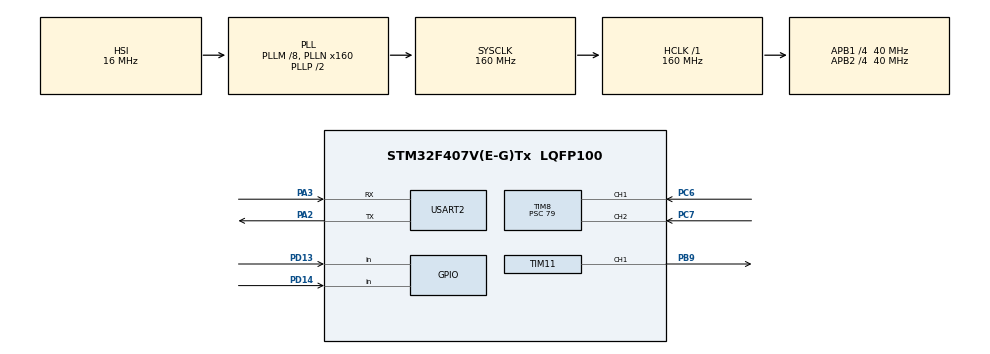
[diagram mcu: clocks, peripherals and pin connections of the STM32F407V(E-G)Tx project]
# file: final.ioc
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Mcu.Family=STM32F4
Mcu.Name=STM32F407V(E-G)Tx
Mcu.Package=LQFP100
NVIC.PriorityGroup=NVIC_PRIORITYGROUP_0
PA2.Mode=Asynchronous
PA2.Signal=USART2_TX
PA3.Mode=Asynchronous
PA3.Signal=USART2_RX
PB9.Signal=S_TIM11_CH1
PC6.Signal=S_TIM8_CH1
PC7.Signal=S_TIM8_CH2
PD13.Signal=GPIO_Input
PD14.Signal=GPIO_Input
ProjectManager.HeapSize=0x200
ProjectManager.StackSize=0x400
ProjectManager.TargetToolchain=STM32CubeIDE
RCC.48MHZClocksFreq_Value=45714285.71428572
RCC.AHBFreq_Value=160000000
RCC.APB1CLKDivider=RCC_HCLK_DIV4
RCC.APB1Freq_Value=40000000
RCC.APB1TimFreq_Value=80000000
RCC.APB2CLKDivider=RCC_HCLK_DIV4
RCC.APB2Freq_Value=40000000
RCC.APB2TimFreq_Value=80000000
RCC.CortexFreq_Value=160000000
RCC.HCLKFreq_Value=160000000
RCC.HSE_VALUE=8000000
RCC.HSI_VALUE=16000000
RCC.PLLM=8
RCC.PLLN=160
RCC.PLLQ=7
RCC.SYSCLKFreq_VALUE=160000000
RCC.SYSCLKSource=RCC_SYSCLKSOURCE_PLLCLK
RCC.VCOOutputFreq_Value=320000000
SH.S_TIM11_CH1.0=TIM11_CH1,PWM Generation1 CH1
SH.S_TIM8_CH1.0=TIM8_CH1,Input_Capture1_from_TI1
SH.S_TIM8_CH2.0=TIM8_CH2,TriggerSource_TI2FP2
SH.S_TIM8_CH2.1=TIM8_CH2,Input_Capture2_from_TI2
TIM11.Channel=TIM_CHANNEL_1
TIM11.Period=39999
TIM11.Prescaler=199
TIM8.Channel-Input_Capture1_from_TI1=TIM_CHANNEL_1
TIM8.Channel-Input_Capture2_from_TI2=TIM_CHANNEL_2
TIM8.ICPolarity_CH1=TIM_INPUTCHANNELPOLARITY_BOTHEDGE
TIM8.ICPolarity_CH2=TIM_INPUTCHANNELPOLARITY_BOTHEDGE
TIM8.Prescaler=79
USART2.VirtualMode=VM_ASYNC
VP_TIM11_VS_ClockSourceINT.Mode=Enable_Timer
VP_TIM8_VS_ControllerModeReset.Mode=Reset Mode
board=STM32F407G-DISC1

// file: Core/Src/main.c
/* USER CODE BEGIN Header */
/**
  ******************************************************************************
  * @file           : main.c
  * @brief          : Main program body
  ******************************************************************************
  * @attention
  *
  * Copyright (c) 2022 STMicroelectronics.
  * All rights reserved.
  *
  * This software is licensed under terms that can be found in the LICENSE file
  * in the root directory of this software component.
  * If no LICENSE file comes with this software, it is provided AS-IS.
  *
  ******************************************************************************
  */
/* USER CODE END Header */
#include "main.h"

//#include "tim.h"
//#include "usart.h"
//#include "gpio.h"

/* USER CODE BEGIN Includes */
#include <stdio.h>
#include <string.h>
#include <stdbool.h>
/* USER CODE END Includes */

 TIM_HandleTypeDef htim8;
TIM_HandleTypeDef htim11;

UART_HandleTypeDef huart2;

/* USER CODE BEGIN PV */

uint32_t echo1, echo2, delay;
float dist1, dist2;
bool on1, on2;

/* USER CODE END PV */

void SystemClock_Config(void);
static void MX_GPIO_Init(void);
static void MX_TIM8_Init(void);
static void MX_TIM11_Init(void);
static void MX_USART2_UART_Init(void);

int main(void)
{

  /* MCU Configuration--------------------------------------------------------*/

  /* Reset of all peripherals, Initializes the Flash interface and the Systick. */
  HAL_Init();

  /* Configure the system clock */
  SystemClock_Config();

  /* Initialize all configured peripherals */
  MX_GPIO_Init();
  MX_TIM8_Init();
  MX_TIM11_Init();
  MX_USART2_UART_Init();
  /* USER CODE BEGIN 2 */
  HAL_TIM_Base_Start(&htim11);
  HAL_TIM_Base_Start(&htim11);
  HAL_TIM_PWM_Start(&htim11, TIM_CHANNEL_1);
  HAL_TIM_IC_Start(&htim8, TIM_CHANNEL_1);
  HAL_TIM_IC_Start(&htim8, TIM_CHANNEL_2);
  TIM11->CCR1 = 3;
  /* USER CODE END 2 */

  /* Infinite loop */
  while (1)
  {

	  // Echo: PC6
	  // Trig: PB9
	  if (HAL_GetTick() - delay >= 100) {
		  delay = HAL_GetTick();
		  echo1 = HAL_TIM_ReadCapturedValue(&htim8, TIM_CHANNEL_1);
		  echo2 = HAL_TIM_ReadCapturedValue(&htim8, TIM_CHANNEL_2);
		  dist1 = echo1 / 58.0f;

		  // camera and range finder on?
		  if (HAL_GPIO_ReadPin(GPIOD,GPIO_PIN_13))
		  {
			  on1 = false;
		  } else {
			  on1 = true;
		  }
		  if (HAL_GPIO_ReadPin(GPIOD,GPIO_PIN_14))
		  {
			  on2 = false;
		  } else {
			  on2 = true;
		  }

		  // Create buffer for distance reading
		  char dist_str[5];

		  // COnvert distance reading to string (in buffer)
		  sprintf(dist_str, "%.2f", dist1);

		  // Create buffer for json string
		  char json[64];

		  // Implement json string w/needed values
		  strcpy(json, "{ \"range\" : ");
		  strcat(json, dist_str);
		  strcat(json, " , \"range_on\" : ");
		  strcat(json, on1 ? "true" : "false");
		  strcat(json, " , \"camera_on\" : ");
		  strcat(json, on2 ? "true" : "false");
		  strcat(json, " }\n"); //create json format output

		  // Uart transmission to rpi
		  HAL_UART_Transmit(&huart2, json, sizeof(json), 10);
//		  HAL_Delay(5000);
	  }

  }
}

void SystemClock_Config(void)
{
  RCC_OscInitTypeDef RCC_OscInitStruct = {0};
  RCC_ClkInitTypeDef RCC_ClkInitStruct = {0};

  /** Configure the main internal regulator output voltage
  */
  __HAL_RCC_PWR_CLK_ENABLE();
  __HAL_PWR_VOLTAGESCALING_CONFIG(PWR_REGULATOR_VOLTAGE_SCALE1);

  /** Initializes the RCC Oscillators according to the specified parameters
  * in the RCC_OscInitTypeDef structure.
  */
  RCC_OscInitStruct.OscillatorType = RCC_OSCILLATORTYPE_HSI;
  RCC_OscInitStruct.HSIState = RCC_HSI_ON;
  RCC_OscInitStruct.HSICalibrationValue = RCC_HSICALIBRATION_DEFAULT;
  RCC_OscInitStruct.PLL.PLLState = RCC_PLL_ON;
  RCC_OscInitStruct.PLL.PLLSource = RCC_PLLSOURCE_HSI;
  RCC_OscInitStruct.PLL.PLLM = 8;
  RCC_OscInitStruct.PLL.PLLN = 160;
  RCC_OscInitStruct.PLL.PLLP = RCC_PLLP_DIV2;
  RCC_OscInitStruct.PLL.PLLQ = 7;
  if (HAL_RCC_OscConfig(&RCC_OscInitStruct) != HAL_OK)
  {
    Error_Handler();
  }

  /** Initializes the CPU, AHB and APB buses clocks
  */
  RCC_ClkInitStruct.ClockType = RCC_CLOCKTYPE_HCLK|RCC_CLOCKTYPE_SYSCLK
                              |RCC_CLOCKTYPE_PCLK1|RCC_CLOCKTYPE_PCLK2;
  RCC_ClkInitStruct.SYSCLKSource = RCC_SYSCLKSOURCE_PLLCLK;
  RCC_ClkInitStruct.AHBCLKDivider = RCC_SYSCLK_DIV1;
  RCC_ClkInitStruct.APB1CLKDivider = RCC_HCLK_DIV4;
  RCC_ClkInitStruct.APB2CLKDivider = RCC_HCLK_DIV4;

  if (HAL_RCC_ClockConfig(&RCC_ClkInitStruct, FLASH_LATENCY_5) != HAL_OK)
  {
    Error_Handler();
  }
}

static void MX_TIM8_Init(void)
{

  TIM_SlaveConfigTypeDef sSlaveConfig = {0};
  TIM_MasterConfigTypeDef sMasterConfig = {0};
  TIM_IC_InitTypeDef sConfigIC = {0};

  htim8.Instance = TIM8;
  htim8.Init.Prescaler = 79;
  htim8.Init.CounterMode = TIM_COUNTERMODE_UP;
  htim8.Init.Period = 65535;
  htim8.Init.ClockDivision = TIM_CLOCKDIVISION_DIV1;
  htim8.Init.RepetitionCounter = 0;
  htim8.Init.AutoReloadPreload = TIM_AUTORELOAD_PRELOAD_DISABLE;
  if (HAL_TIM_Base_Init(&htim8) != HAL_OK)
  {
    Error_Handler();
  }
  if (HAL_TIM_IC_Init(&htim8) != HAL_OK)
  {
    Error_Handler();
  }
  sSlaveConfig.SlaveMode = TIM_SLAVEMODE_RESET;
  sSlaveConfig.InputTrigger = TIM_TS_TI2FP2;
  sSlaveConfig.TriggerPolarity = TIM_INPUTCHANNELPOLARITY_BOTHEDGE;
  sSlaveConfig.TriggerFilter = 0;
  if (HAL_TIM_SlaveConfigSynchro(&htim8, &sSlaveConfig) != HAL_OK)
  {
    Error_Handler();
  }
  sMasterConfig.MasterOutputTrigger = TIM_TRGO_RESET;
  sMasterConfig.MasterSlaveMode = TIM_MASTERSLAVEMODE_DISABLE;
  if (HAL_TIMEx_MasterConfigSynchronization(&htim8, &sMasterConfig) != HAL_OK)
  {
    Error_Handler();
  }
  sConfigIC.ICPolarity = TIM_INPUTCHANNELPOLARITY_BOTHEDGE;
  sConfigIC.ICSelection = TIM_ICSELECTION_DIRECTTI;
  sConfigIC.ICPrescaler = TIM_ICPSC_DIV1;
  sConfigIC.ICFilter = 0;
  if (HAL_TIM_IC_ConfigChannel(&htim8, &sConfigIC, TIM_CHANNEL_1) != HAL_OK)
  {
    Error_Handler();
  }
  if (HAL_TIM_IC_ConfigChannel(&htim8, &sConfigIC, TIM_CHANNEL_2) != HAL_OK)
  {
    Error_Handler();
  }

}

static void MX_TIM11_Init(void)
{

  TIM_OC_InitTypeDef sConfigOC = {0};

  htim11.Instance = TIM11;
  htim11.Init.Prescaler = 199;
  htim11.Init.CounterMode = TIM_COUNTERMODE_UP;
  htim11.Init.Period = 39999;
  htim11.Init.ClockDivision = TIM_CLOCKDIVISION_DIV1;
  htim11.Init.AutoReloadPreload = TIM_AUTORELOAD_PRELOAD_DISABLE;
  if (HAL_TIM_Base_Init(&htim11) != HAL_OK)
  {
    Error_Handler();
  }
  if (HAL_TIM_PWM_Init(&htim11) != HAL_OK)
  {
    Error_Handler();
  }
  sConfigOC.OCMode = TIM_OCMODE_PWM1;
  sConfigOC.Pulse = 0;
  sConfigOC.OCPolarity = TIM_OCPOLARITY_HIGH;
  sConfigOC.OCFastMode = TIM_OCFAST_DISABLE;
  if (HAL_TIM_PWM_ConfigChannel(&htim11, &sConfigOC, TIM_CHANNEL_1) != HAL_OK)
  {
    Error_Handler();
  }
  HAL_TIM_MspPostInit(&htim11);

}

static void MX_USART2_UART_Init(void)
{

  huart2.Instance = USART2;
  huart2.Init.BaudRate = 115200;
  huart2.Init.WordLength = UART_WORDLENGTH_8B;
  huart2.Init.StopBits = UART_STOPBITS_1;
  huart2.Init.Parity = UART_PARITY_NONE;
  huart2.Init.Mode = UART_MODE_TX_RX;
  huart2.Init.HwFlowCtl = UART_HWCONTROL_NONE;
  huart2.Init.OverSampling = UART_OVERSAMPLING_16;
  if (HAL_UART_Init(&huart2) != HAL_OK)
  {
    Error_Handler();
  }

}

static void MX_GPIO_Init(void)
{
  GPIO_InitTypeDef GPIO_InitStruct = {0};

  /* GPIO Ports Clock Enable */
  __HAL_RCC_GPIOA_CLK_ENABLE();
  __HAL_RCC_GPIOD_CLK_ENABLE();
  __HAL_RCC_GPIOC_CLK_ENABLE();
  __HAL_RCC_GPIOB_CLK_ENABLE();

  /*Configure GPIO pin : PD14 */
  GPIO_InitStruct.Pin = GPIO_PIN_14 | GPIO_PIN_13;
  GPIO_InitStruct.Mode = GPIO_MODE_INPUT;
  GPIO_InitStruct.Pull = GPIO_NOPULL;
  HAL_GPIO_Init(GPIOD, &GPIO_InitStruct);

}

void Error_Handler(void)
{
  __disable_irq();
  while (1)
  {
  }
}
